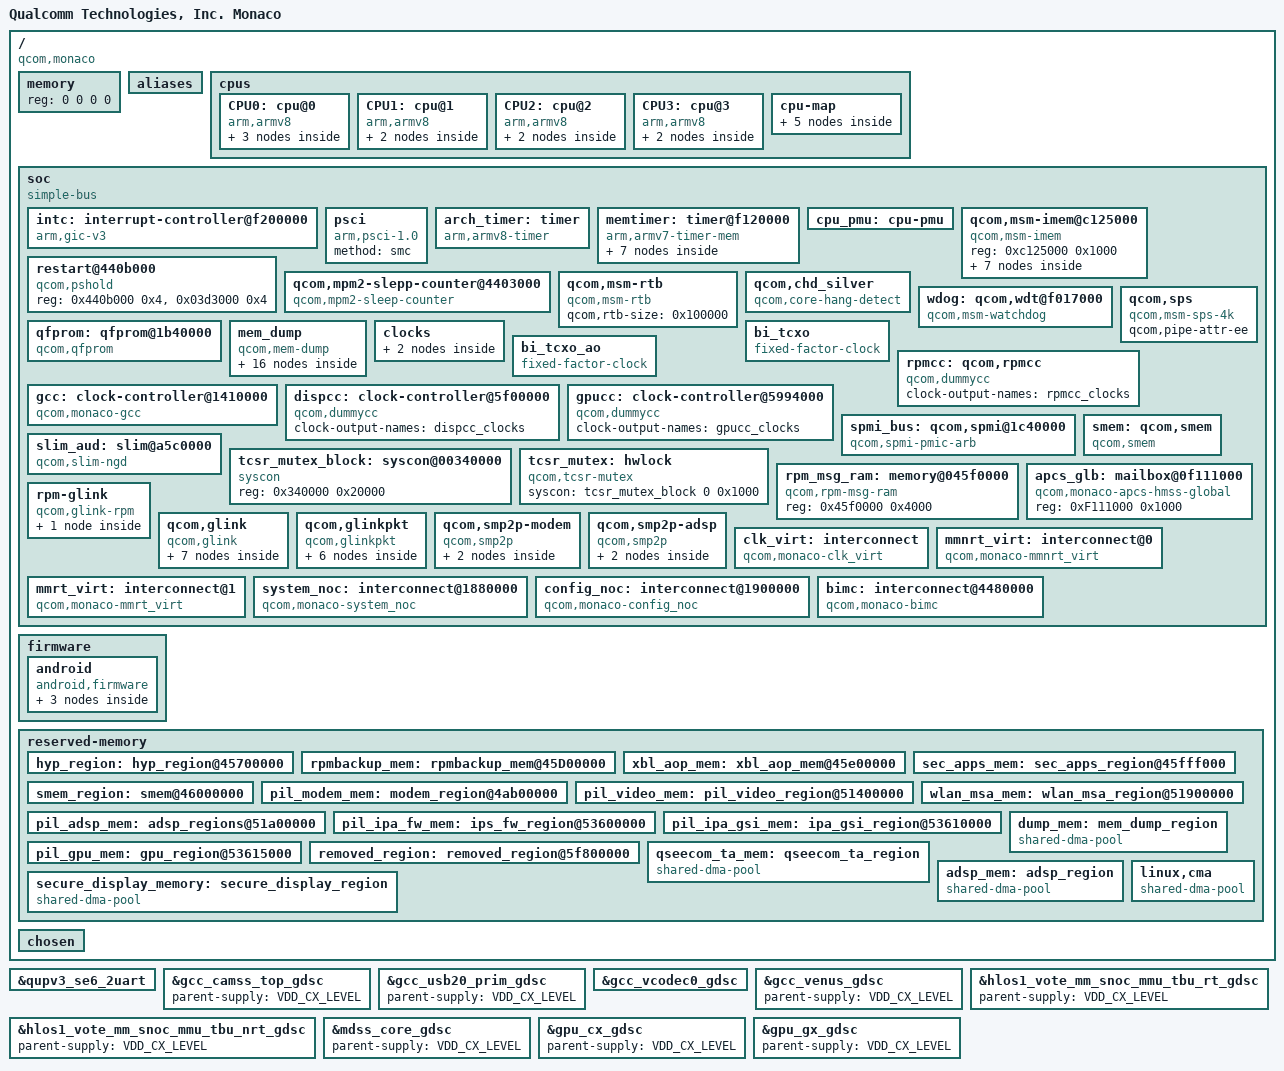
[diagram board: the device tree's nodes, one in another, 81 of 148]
#include <dt-bindings/interrupt-controller/arm-gic.h>
#include <dt-bindings/clock/qcom,rpmcc.h>
#include <dt-bindings/clock/qcom,dispcc-monaco.h>
#include <dt-bindings/clock/qcom,gcc-monaco.h>
#include <dt-bindings/clock/qcom,gpucc-monaco.h>
#include <dt-bindings/interconnect/qcom,monaco.h>
#include <dt-bindings/interconnect/qcom,icc.h>


/ {
	model = "Qualcomm Technologies, Inc. Monaco";
	compatible = "qcom,monaco";
	qcom,msm-id = <486 0x10000>;
	interrupt-parent = <&intc>;

	#address-cells = <2>;
	#size-cells = <2>;
	memory { device_type = "memory"; reg = <0 0 0 0>; };

	aliases {
		serial0 = &qupv3_se6_2uart;
		hsuart0 = &qupv3_se5_4uart;
	};

	cpus {
		#address-cells = <2>;
		#size-cells = <0>;

		CPU0: cpu@0 {
			device_type = "cpu";
			compatible = "arm,armv8";
			reg = <0x0 0x0>;
			enable-method = "psci";
			d-cache-size = <0x8000>;
			i-cache-size = <0x8000>;
			next-level-cache = <&L2_0>;
			L2_0: l2-cache {
			      compatible = "arm,arch-cache";
			      cache-size = <0x80000>;
			      cache-level = <2>;
			};

			L1_I_0: l1-icache {
			      compatible = "arm,arch-cache";
			};

			L1_D_0: l1-dcache {
			      compatible = "arm,arch-cache";
			};
		};

		CPU1: cpu@1 {
			device_type = "cpu";
			compatible = "arm,armv8";
			reg = <0x0 0x1>;
			enable-method = "psci";
			d-cache-size = <0x8000>;
			i-cache-size = <0x8000>;
			next-level-cache = <&L2_0>;

			L1_I_1: l1-icache {
			      compatible = "arm,arch-cache";
			};

			L1_D_1: l1-dcache {
			      compatible = "arm,arch-cache";
			};
		};

		CPU2: cpu@2 {
			device_type = "cpu";
			compatible = "arm,armv8";
			reg = <0x0 0x2>;
			enable-method = "psci";
			d-cache-size = <0x8000>;
			i-cache-size = <0x8000>;
			next-level-cache = <&L2_0>;

			L1_I_2: l1-icache {
			      compatible = "arm,arch-cache";
			};

			L1_D_2: l1-dcache {
			      compatible = "arm,arch-cache";
			};
		};

		CPU3: cpu@3 {
			device_type = "cpu";
			compatible = "arm,armv8";
			reg = <0x0 0x3>;
			enable-method = "psci";
			d-cache-size = <0x8000>;
			i-cache-size = <0x8000>;
			next-level-cache = <&L2_0>;

			L1_I_3: l1-icache {
			      compatible = "arm,arch-cache";
			};

			L1_D_3: l1-dcache {
			      compatible = "arm,arch-cache";
			};

		};

		cpu-map {
			cluster0 {
				core0 {
					cpu = <&CPU0>;
				};

				core1 {
					cpu = <&CPU1>;
				};

				core2 {
					cpu = <&CPU2>;
				};

				core3 {
					cpu = <&CPU3>;
				};
			};
		};
	};

	soc: soc { };

	firmware: firmware {
		android {
			compatible = "android,firmware";
			vbmeta {
				compatible="android,vbmeta";
				parts = "vbmeta,boot,system,vendor,dtbo,recovery";
			};

			fstab {
				compatible = "android,fstab";
				vendor {
					compatible = "android,vendor";
					dev =
			"/dev/block/platform/soc/4744000.sdhci/by-name/vendor";
					type = "ext4";
					mnt_flags = "ro,barrier=1,discard";
					fsmgr_flags = "wait,slotselect,avb";
					status = "ok";
				};
			};
		};
	};

	reserved-memory {
		#address-cells = <2>;
		#size-cells = <2>;
		ranges;

		hyp_region: hyp_region@45700000 {
			no-map;
			reg = <0x0 0x45700000 0x0 0x600000>;
		};

		rpmbackup_mem: rpmbackup_mem@45D00000 {
			no-map;
			reg = <0x0 0x45D00000 0x0 0x100000>;
		};

		xbl_aop_mem: xbl_aop_mem@45e00000 {
			no-map;
			reg = <0x0 0x45e00000 0x0 0x110000>;
		};

		sec_apps_mem: sec_apps_region@45fff000 {
			no-map;
			reg = <0x0 0x45fff000 0x0 0x1000>;
		};

		smem_region: smem@46000000 {
			no-map;
			reg = <0x0 0x46000000 0x0 0x200000>;
		};

		pil_modem_mem: modem_region@4ab00000 {
			no-map;
			reg = <0x0 0x4ab00000 0x0 0x6900000>;
		};

		pil_video_mem: pil_video_region@51400000 {
			no-map;
			reg = <0x0 0x51400000 0x0 0x500000>;
		};

		wlan_msa_mem: wlan_msa_region@51900000 {
			no-map;
			reg = <0x0 0x51900000 0x0 0x100000>;
		};

		pil_adsp_mem: adsp_regions@51a00000 {
			no-map;
			reg = <0x0 0x51a00000 0x0 0x1c00000>;
		};

		pil_ipa_fw_mem: ips_fw_region@53600000 {
			no-map;
			reg = <0x0 0x53600000 0x0 0x10000>;
		};

		pil_ipa_gsi_mem: ipa_gsi_region@53610000 {
			no-map;
			reg = <0x0 0x53610000 0x0 0x5000>;
		};

		pil_gpu_mem: gpu_region@53615000 {
			no-map;
			reg = <0x0 0x53615000 0x0 0x2000>;
		};

		removed_region: removed_region@5f800000 {
			no-map;
			reg = <0x0 0x5f800000 0x0 0x2700000>;
		};

		dump_mem: mem_dump_region {
			compatible = "shared-dma-pool";
			reusable;
			size = <0 0x800000>;
		};

		qseecom_ta_mem: qseecom_ta_region {
			compatible = "shared-dma-pool";
			alloc-ranges = <0x0 0x00000000 0x0 0xffffffff>;
			reusable;
			alignment = <0x0 0x400000>;
			size = <0x0 0x1000000>;
		};

		secure_display_memory: secure_display_region {
			compatible = "shared-dma-pool";
			alloc-ranges = <0 0x00000000 0 0xffffffff>;
			reusable;
			alignment = <0 0x400000>;
			size = <0 0x5c00000>;
		};

		adsp_mem: adsp_region {
			compatible = "shared-dma-pool";
			alloc-ranges = <0 0x00000000 0 0xffffffff>;
			reusable;
			alignment = <0 0x400000>;
			size = <0 0x800000>;
		};

		/* global autoconfigured region for contiguous allocations */
		linux,cma {
			compatible = "shared-dma-pool";
			alloc-ranges = <0x0 0x00000000 0x0 0xffffffff>;
			reusable;
			alignment = <0x0 0x400000>;
			size = <0x0 0x2000000>;
			linux,cma-default;
		};
	};

	chosen {
		bootargs = "rcupdate.rcu_expedited=1 rcu_nocbs=0-7";
	};
};

&soc {
	#address-cells = <1>;
	#size-cells = <1>;
	ranges = <0 0 0 0xffffffff>;
	#gpio-cells = <2>;
	compatible = "simple-bus";

	intc: interrupt-controller@f200000 {
		compatible = "arm,gic-v3";
		#interrupt-cells = <3>;
		interrupt-controller;
		#redistributor-regions = <1>;
		redistributor-stride = <0x0 0x20000>;
		reg = <0xf200000 0x10000>,     /* GICD */
		      <0xf300000 0x100000>;    /* GICR * 8 */
		interrupts = <GIC_PPI 9 IRQ_TYPE_LEVEL_HIGH>;
	};

	psci {
		compatible = "arm,psci-1.0";
		method = "smc";
	};

	arch_timer: timer {
		compatible = "arm,armv8-timer";
		interrupts = <GIC_PPI 1 (GIC_CPU_MASK_SIMPLE(8) | IRQ_TYPE_LEVEL_LOW)>,
			     <GIC_PPI 2 (GIC_CPU_MASK_SIMPLE(8) | IRQ_TYPE_LEVEL_LOW)>,
			     <GIC_PPI 3 (GIC_CPU_MASK_SIMPLE(8) | IRQ_TYPE_LEVEL_LOW)>,
			     <GIC_PPI 0 (GIC_CPU_MASK_SIMPLE(8) | IRQ_TYPE_LEVEL_LOW)>;
		clock-frequency = <19200000>;
	};

	memtimer: timer@f120000 {
		#address-cells = <1>;
		#size-cells = <1>;
		ranges;
		compatible = "arm,armv7-timer-mem";
		reg = <0x0f120000 0x1000>;
		clock-frequency = <19200000>;

		frame@f121000 {
			frame-number = <0>;
			interrupts = <GIC_SPI 8 IRQ_TYPE_LEVEL_HIGH>,
				     <GIC_SPI 7 IRQ_TYPE_LEVEL_HIGH>;
			reg = <0x0f121000 0x1000>,
			      <0x0f122000 0x1000>;
		};

		frame@f123000 {
			frame-number = <1>;
			interrupts = <GIC_SPI 9 IRQ_TYPE_LEVEL_HIGH>;
			reg = <0xf123000 0x1000>;
			status = "disabled";
		};

		frame@f124000 {
			frame-number = <2>;
			interrupts = <GIC_SPI 10 IRQ_TYPE_LEVEL_HIGH>;
			reg = <0xf124000 0x1000>;
			status = "disabled";
		};

		frame@f125000 {
			frame-number = <3>;
			interrupts = <GIC_SPI 11 IRQ_TYPE_LEVEL_HIGH>;
			reg = <0xf125000 0x1000>;
			status = "disabled";
		};

		frame@f126000 {
			frame-number = <4>;
			interrupts = <GIC_SPI 12 IRQ_TYPE_LEVEL_HIGH>;
			reg = <0xf126000 0x1000>;
			status = "disabled";
		};

		frame@f127000 {
			frame-number = <5>;
			interrupts = <GIC_SPI 13 IRQ_TYPE_LEVEL_HIGH>;
			reg = <0xf127000 0x1000>;
			status = "disabled";
		};

		frame@f128000 {
			frame-number = <6>;
			interrupts = <GIC_SPI 14 IRQ_TYPE_LEVEL_HIGH>;
			reg = <0xf128000 0x1000>;
			status = "disabled";
		};
	};

	cpu_pmu: cpu-pmu {
		ompatible = "arm,armv8-pmuv3";
		qcom,irq-is-percpu;
		interrupts = <GIC_PPI 6 IRQ_TYPE_LEVEL_HIGH>;
	};

	qcom,msm-imem@c125000 {
		compatible = "qcom,msm-imem";
		reg = <0xc125000 0x1000>;
		ranges = <0x0 0xc125000 0x1000>;
		#address-cells = <1>;
		#size-cells = <1>;

		mem_dump_table@10 {
			compatible = "qcom,msm-imem-mem_dump_table";
			reg = <0x10 0x8>;
		};

		restart_reason@65c {
			compatible = "qcom,msm-imem-restart_reason";
			reg = <0x65c 0x4>;
		};

		dload_type@1c {
			compatible = "qcom,msm-imem-dload-type";
			reg = <0x1c 0x4>;
		};

		boot_stats@6b0 {
			compatible = "qcom,msm-imem-boot_stats";
			reg = <0x6b0 0x20>;
		};

		kaslr_offset@6d0 {
			compatible = "qcom,msm-imem-kaslr_offset";
			reg = <0x6d0 0xc>;
		};

		pil@94c {
			compatible = "qcom,msm-imem-pil";
			reg = <0x94c 0xc8>;
		};

		diag_dload@c8 {
			compatible = "qcom,msm-imem-diag-dload";
			reg = <0xc8 0xc8>;
		};
	};

	restart@440b000 {
		compatible = "qcom,pshold";
		reg = <0x440b000 0x4>, <0x03d3000 0x4>;
		reg-names = "pshold-base", "tcsr-boot-misc-detect";
	};

	qcom,mpm2-slepp-counter@4403000 {
		compatible = "qcom,mpm2-sleep-counter";
		reg = <0x4403000 0x1000>;
		clock-frequency = <32768>;
	};

	qcom,msm-rtb {
		compatible = "qcom,msm-rtb";
		qcom,rtb-size = <0x100000>;
	};

	qcom,chd_silver {
		compatible = "qcom,core-hang-detect";
		label = "silver";
		qcom,threshold-arr = <0x0f1880b0 0x0f1980b0
				      0x0f1a80b0 0x0f1b80b0>;
		qcom,config-arr = <0x0f1880b8 0x0f1980b8
				   0x0f1a80b8 0x0f1b80b8>;
	};

	wdog: qcom,wdt@f017000 {
		compatible = "qcom,msm-watchdog";
		reg = <0xf017000 0x1000>;
		reg-names = "wdt-base";
		interrupts = <GIC_SPI 3 IRQ_TYPE_LEVEL_HIGH>,
			     <GIC_SPI 4 IRQ_TYPE_LEVEL_HIGH>;
		qcom,bark-time = <11000>;
		qcom,pet-time = <9360>;
		qcom,ipi-ping;
		qcom,wakeup-enable;
	};

	qcom,sps {
		compatible = "qcom,msm-sps-4k";
		qcom,pipe-attr-ee;
	};

	qfprom: qfprom@1b40000 {
		compatible = "qcom,qfprom";
		reg = <0x1b40000 0x7000>;
		#address-cells = <1>;
		#size-cells = <1>;
		read-only;
		ranges;
	};

	mem_dump {
		compatible = "qcom,mem-dump";

		c0_context {
			qcom,dump-size = <0x800>;
			qcom,dump-id = <0x0>;
		};

		c1_context {
			qcom,dump-size = <0x800>;
			qcom,dump-id = <0x1>;
		};

		c2_context {
			qcom,dump-size = <0x800>;
			qcom,dump-id = <0x2>;
		};

		c3_context {
			qcom,dump-size = <0x800>;
			qcom,dump-id = <0x3>;
		};

		l1_icache0 {
			qcom,dump-size = <0x9040>;
			qcom,dump-id = <0x60>;
		};

		l1_icache1 {
			qcom,dump-size = <0x9040>;
			qcom,dump-id = <0x61>;
		};

		l1_icache2 {
			qcom,dump-size = <0x9040>;
			qcom,dump-id = <0x62>;
		};

		l1_icache3 {
			qcom,dump-size = <0x9040>;
			qcom,dump-id = <0x63>;
		};

		l1_dcache0 {
			qcom,dump-size = <0x9040>;
			qcom,dump-id = <0x80>;
		};

		l1_dcache1 {
			qcom,dump-size = <0x9040>;
			qcom,dump-id = <0x81>;
		};

		l1_dcache2 {
			qcom,dump-size = <0x9040>;
			qcom,dump-id = <0x82>;
		};

		l1_dcache3 {
			qcom,dump-size = <0x9040>;
			qcom,dump-id = <0x83>;
		};

		l2_tlb0 {
			qcom,dump-size = <0x2000>;
			qcom,dump-id = <0x120>;
		};

		l2_tlb1 {
			qcom,dump-size = <0x2000>;
			qcom,dump-id = <0x121>;
		};

		l2_tlb2 {
			qcom,dump-size = <0x2000>;
			qcom,dump-id = <0x122>;
		};

		l2_tlb3 {
			qcom,dump-size = <0x2000>;
			qcom,dump-id = <0x123>;
		};
	};

	clocks {
		xo_board: xo-board {
			compatible = "fixed-clock";
			clock-frequency = <38400000>;
			clock-output-names = "xo_board";
			#clock-cells = <0>;
		};

		sleep_clk: sleep-clk {
			compatible = "fixed-clock";
			clock-frequency = <32000>;
			clock-output-names = "sleep_clk";
			#clock-cells = <0>;
		};
	};

	bi_tcxo: bi_tcxo {
		compatible = "fixed-factor-clock";
		clock-mult = <1>;
		clock-div = <2>;
		clocks = <&xo_board>;
		#clock-cells = <0>;
	};

	bi_tcxo_ao: bi_tcxo_ao {
		compatible = "fixed-factor-clock";
		clock-mult = <1>;
		clock-div = <2>;
		clocks = <&xo_board>;
		#clock-cells = <0>;
	};

	rpmcc: qcom,rpmcc {
		compatible = "qcom,dummycc";
		clock-output-names = "rpmcc_clocks";
		#clock-cells = <1>;
		#reset-cells = <1>;
	};

	gcc: clock-controller@1410000 {
		compatible = "qcom,monaco-gcc", "syscon";
		reg = <0x1400000 0x1e0000>;
		reg-names = "cc_base";
		vdd_cx-supply = <&VDD_CX_LEVEL>;
		vdd_mx-supply = <&VDD_MXA_LEVEL>;
		clocks = <&rpmcc RPM_SMD_XO_CLK_SRC>,
			 <&rpmcc RPM_SMD_XO_A_CLK_SRC>,
			 <&sleep_clk>;
		clock-names = "bi_tcxo", "bi_tcxo_ao", "sleep_clk";
		#clock-cells = <1>;
		#reset-cells = <1>;
	};

	dispcc: clock-controller@5f00000 {
		compatible = "qcom,dummycc";
		clock-output-names = "dispcc_clocks";
		#clock-cells = <1>;
		#reset-cells = <1>;
	};

	gpucc: clock-controller@5994000 {
		compatible = "qcom,dummycc";
		clock-output-names = "gpucc_clocks";
		#clock-cells = <1>;
		#reset-cells = <1>;
	};

	spmi_bus: qcom,spmi@1c40000 {
		compatible = "qcom,spmi-pmic-arb";
		reg = <0x1c40000 0x1100>,
			<0x1e00000 0x2000000>,
			<0x3e00000 0x100000>,
			<0x3f00000 0xa0000>,
			<0x1c0a000 0x26000>;
		reg-names = "core", "chnls", "obsrvr", "intr", "cnfg";
		interrupt-names = "periph_irq";
		interrupts = <GIC_SPI 183 IRQ_TYPE_LEVEL_HIGH>;
		qcom,ee = <0>;
		qcom,channel = <0>;
		#address-cells = <2>;
		#size-cells = <0>;
		interrupt-controller;
		#interrupt-cells = <4>;
		cell-index = <0>;
	};

	slim_aud: slim@a5c0000 {
		cell-index = <1>;
		compatible = "qcom,slim-ngd";
		reg = <0xa5c0000 0x2c000>,
			<0xa584000 0x20000>, <0xa66e000 0x2000>;
		reg-names = "slimbus_physical",
			"slimbus_bam_physical", "slimbus_lpass_mem";
		interrupts = <GIC_SPI 283 IRQ_TYPE_LEVEL_HIGH>,
				<GIC_SPI 284 IRQ_TYPE_LEVEL_HIGH>;
		interrupt-names = "slimbus_irq", "slimbus_bam_irq";
		qcom,apps-ch-pipes = <0x0>;
		qcom,ea-pc = <0x3f0>;
		status = "ok";
	};

	tcsr_mutex_block: syscon@00340000 {
		compatible = "syscon";
		reg = <0x340000 0x20000>;
	};

	tcsr_mutex: hwlock {
		compatible = "qcom,tcsr-mutex";
		syscon = <&tcsr_mutex_block 0 0x1000>;
		#hwlock-cells = <1>;
	};

	smem: qcom,smem {
		compatible = "qcom,smem";
		memory-region = <&smem_region>;
		hwlocks = <&tcsr_mutex 3>;
	};

	rpm_msg_ram: memory@045f0000 {
			compatible = "qcom,rpm-msg-ram";
			reg = <0x45f0000 0x4000>;
	};

	apcs_glb: mailbox@0f111000 {
		compatible = "qcom,monaco-apcs-hmss-global";
		reg = <0xF111000 0x1000>;

		#mbox-cells = <1>;
	};

	rpm-glink {
		compatible = "qcom,glink-rpm";
		interrupts = <GIC_SPI 194 IRQ_TYPE_EDGE_RISING>;
		qcom,rpm-msg-ram = <&rpm_msg_ram>;
		mboxes = <&apcs_glb 0>;

		qcom,rpm_glink_ssr {
			qcom,glink-channels = "glink_ssr";
			qcom,notify-edges = <&glink_modem>,
						<&glink_adsp>;
		};

	};

	qcom,glink {
		compatible = "qcom,glink";
		#address-cells = <1>;
		#size-cells = <1>;
		ranges;

		glink_modem: modem {
			qcom,remote-pid = <1>;
			transport = "smem";
			mboxes = <&apcs_glb 12>;
			mbox-names = "mpss_smem";
			interrupts = <GIC_SPI 68 IRQ_TYPE_EDGE_RISING>;

			label = "modem";
			qcom,glink-label = "mpss";

			qcom,modem_qrtr {
				qcom,glink-channels = "IPCRTR";
				qcom,low-latency;
				qcom,intents = <0x800  5
						0x2000 3
						0x4400 2>;
			};

			qcom,modem_ds {
				qcom,glink-channels = "DS";
				qcom,intents = <0x4000 2>;
			};

			qcom,modem_glink_ssr {
				qcom,glink-channels = "glink_ssr";
				qcom,notify-edges = <&glink_adsp>;
			};
		};

		glink_adsp: adsp {
			qcom,remote-pid = <2>;
			transport = "smem";
			mboxes = <&apcs_glb 8>;
			mbox-names = "adsp_smem";
			interrupts = <GIC_SPI 277 IRQ_TYPE_EDGE_RISING>;

			label = "adsp";
			qcom,glink-label = "lpass";

			qcom,adsp_qrtr {
				qcom,glink-channels = "IPCRTR";
				qcom,low-latency;
				qcom,intents = <0x800  5
						0x2000 3
						0x4400 2>;
			};

			qcom,adsp_glink_ssr {
				qcom,glink-channels = "glink_ssr";
				qcom,notify-edges = <&glink_modem>;
			};
		};
	};

	qcom,glinkpkt {
		compatible = "qcom,glinkpkt";

		qcom,glinkpkt-at-mdm0 {
			qcom,glinkpkt-edge = "mpss";
			qcom,glinkpkt-ch-name = "DS";
			qcom,glinkpkt-dev-name = "at_mdm0";
		};

		qcom,glinkpkt-apr-apps2 {
			qcom,glinkpkt-edge = "adsp";
			qcom,glinkpkt-ch-name = "apr_apps2";
			qcom,glinkpkt-dev-name = "apr_apps2";
		};

		qcom,glinkpkt-data40-cntl {
			qcom,glinkpkt-edge = "mpss";
			qcom,glinkpkt-ch-name = "DATA40_CNTL";
			qcom,glinkpkt-dev-name = "smdcntl8";
		};

		qcom,glinkpkt-data1 {
			qcom,glinkpkt-edge = "mpss";
			qcom,glinkpkt-ch-name = "DATA1";
			qcom,glinkpkt-dev-name = "smd7";
		};

		qcom,glinkpkt-data4 {
			qcom,glinkpkt-edge = "mpss";
			qcom,glinkpkt-ch-name = "DATA4";
			qcom,glinkpkt-dev-name = "smd8";
		};

		qcom,glinkpkt-data11 {
			qcom,glinkpkt-edge = "mpss";
			qcom,glinkpkt-ch-name = "DATA11";
			qcom,glinkpkt-dev-name = "smd11";
		};
	};

	qcom,smp2p-modem {
		compatible = "qcom,smp2p";
		qcom,smem = <435>, <428>;
		interrupts = <GIC_SPI 70 IRQ_TYPE_EDGE_RISING>;
		mboxes = <&apcs_glb 14>;
		qcom,local-pid = <0>;
		qcom,remote-pid = <1>;

		modem_smp2p_out: master-kernel {
			qcom,entry-name = "master-kernel";
			#qcom,smem-state-cells = <1>;
		};

		modem_smp2p_in: slave-kernel {
			qcom,entry-name = "slave-kernel";
			interrupt-controller;
			#interrupt-cells = <2>;
		};
	};

	qcom,smp2p-adsp {
		compatible = "qcom,smp2p";
		qcom,smem = <443>, <429>;
		interrupts = <GIC_SPI 279 IRQ_TYPE_EDGE_RISING>;
		mboxes = <&apcs_glb 10>;
		qcom,local-pid = <0>;
		qcom,remote-pid = <2>;

		adsp_smp2p_out: master-kernel {
			qcom,entry-name = "master-kernel";
			#qcom,smem-state-cells = <1>;
		};

		adsp_smp2p_in: slave-kernel {
			qcom,entry-name = "slave-kernel";
			interrupt-controller;
			#interrupt-cells = <2>;
		};
	};

	clk_virt: interconnect {
		compatible = "qcom,monaco-clk_virt";
		#interconnect-cells = <1>;
	};

	mmnrt_virt: interconnect@0 {
		compatible = "qcom,monaco-mmnrt_virt";
		#interconnect-cells = <1>;
	};

	mmrt_virt: interconnect@1 {
		compatible = "qcom,monaco-mmrt_virt";
		#interconnect-cells = <1>;
	};

	system_noc: interconnect@1880000 {
		compatible = "qcom,monaco-system_noc";
		#interconnect-cells = <1>;
	};

	config_noc: interconnect@1900000 {
		compatible = "qcom,monaco-config_noc";
		#interconnect-cells = <1>;
	};

	bimc: interconnect@4480000 {
		compatible = "qcom,monaco-bimc";
		#interconnect-cells = <1>;
	};
};

#include "monaco-pinctrl.dtsi"
#include "msm-arm-smmu-monaco.dtsi"
#include "monaco-ion.dtsi"
#include "monaco-stub-regulator.dtsi"
#include "monaco-gdsc.dtsi"
#include "monaco-qupv3.dtsi"

&qupv3_se6_2uart {
	status = "ok";
};

&gcc_camss_top_gdsc {
	parent-supply = <&VDD_CX_LEVEL>;
	status = "ok";
};

&gcc_usb20_prim_gdsc {
	parent-supply = <&VDD_CX_LEVEL>;
	status = "ok";
};

&gcc_vcodec0_gdsc {
	qcom,support-hw-trigger;
	parent-supply = <&VDD_CX_LEVEL>;
	status = "ok";
};

&gcc_venus_gdsc {
	parent-supply = <&VDD_CX_LEVEL>;
	status = "ok";
};

&hlos1_vote_mm_snoc_mmu_tbu_rt_gdsc {
	parent-supply = <&VDD_CX_LEVEL>;
	status = "ok";
};

&hlos1_vote_mm_snoc_mmu_tbu_nrt_gdsc {
	parent-supply = <&VDD_CX_LEVEL>;
	status = "ok";
};

&mdss_core_gdsc {
	parent-supply = <&VDD_CX_LEVEL>;
	status = "ok";
};

&gpu_cx_gdsc {
	parent-supply = <&VDD_CX_LEVEL>;
	status = "ok";
};

&gpu_gx_gdsc {
	parent-supply = <&VDD_CX_LEVEL>;
	status = "ok";
};
